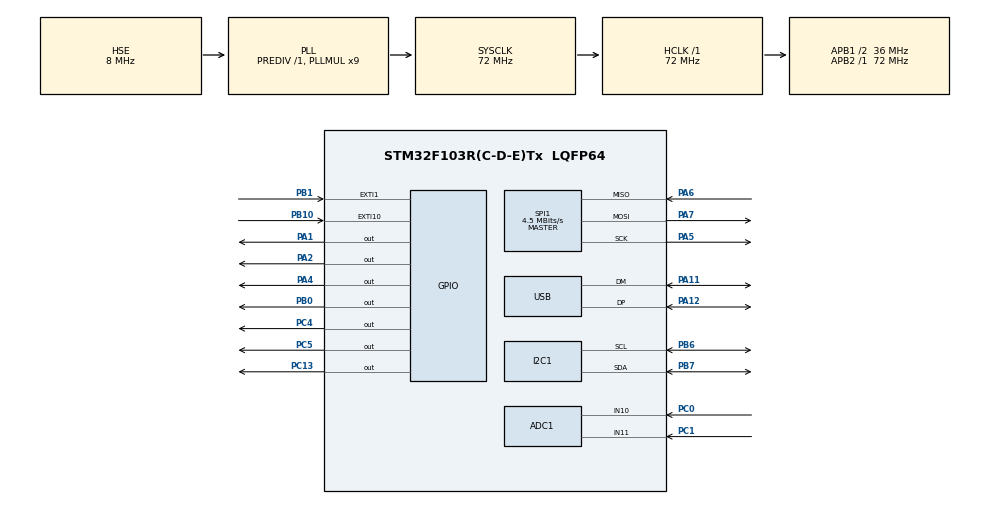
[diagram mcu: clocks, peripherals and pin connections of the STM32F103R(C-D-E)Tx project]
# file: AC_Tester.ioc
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ADC1.Channel-0\#ChannelRegularConversion=ADC_CHANNEL_11
ADC1.Channel-1\#ChannelRegularConversion=ADC_CHANNEL_10
ADC1.ContinuousConvMode=DISABLE
ADC1.ExternalTrigConv=ADC_EXTERNALTRIGCONV_T3_TRGO
ADC1.NbrOfConversion=2
ADC1.NbrOfConversionFlag=1
ADC1.Rank-0\#ChannelRegularConversion=1
ADC1.Rank-1\#ChannelRegularConversion=2
ADC1.SamplingTime-0\#ChannelRegularConversion=ADC_SAMPLETIME_1CYCLE_5
ADC1.SamplingTime-1\#ChannelRegularConversion=ADC_SAMPLETIME_1CYCLE_5
ADC1.master=1
Dma.ADC1.0.Direction=DMA_PERIPH_TO_MEMORY
Dma.ADC1.0.Instance=DMA1_Channel1
Dma.ADC1.0.MemDataAlignment=DMA_MDATAALIGN_HALFWORD
Dma.ADC1.0.MemInc=DMA_MINC_ENABLE
Dma.ADC1.0.Mode=DMA_CIRCULAR
Dma.ADC1.0.PeriphDataAlignment=DMA_PDATAALIGN_HALFWORD
Dma.ADC1.0.PeriphInc=DMA_PINC_DISABLE
Dma.ADC1.0.Priority=DMA_PRIORITY_LOW
Dma.Request0=ADC1
I2C1.I2C_Mode=I2C_Fast
Mcu.Family=STM32F1
Mcu.Name=STM32F103R(C-D-E)Tx
Mcu.Package=LQFP64
NVIC.DMA1_Channel1_IRQn=true\:0\:0\:false\:false\:true\:false\:true\:true
NVIC.EXTI1_IRQn=true\:1\:0\:true\:false\:true\:true\:true\:true
NVIC.PriorityGroup=NVIC_PRIORITYGROUP_4
NVIC.TIM2_IRQn=true\:0\:0\:false\:false\:true\:true\:true\:true
NVIC.USB_LP_CAN1_RX0_IRQn=true\:0\:0\:false\:false\:true\:false\:true\:true
PA1.Signal=GPIO_Output
PA11.Mode=Device
PA11.Signal=USB_DM
PA12.Mode=Device
PA12.Signal=USB_DP
PA13.Mode=Trace_Asynchronous_SW
PA13.Signal=SYS_JTMS-SWDIO
PA14.Mode=Trace_Asynchronous_SW
PA14.Signal=SYS_JTCK-SWCLK
PA2.Signal=GPIO_Output
PA4.Signal=GPIO_Output
PA5.Mode=Full_Duplex_Master
PA5.Signal=SPI1_SCK
PA6.Mode=Full_Duplex_Master
PA6.Signal=SPI1_MISO
PA7.Mode=Full_Duplex_Master
PA7.Signal=SPI1_MOSI
PB0.Signal=GPIO_Output
PB1.GPIO_ModeDefaultEXTI=GPIO_MODE_IT_RISING_FALLING
PB1.Signal=GPXTI1
PB10.GPIO_ModeDefaultEXTI=GPIO_MODE_IT_FALLING
PB10.Signal=GPXTI10
PB3.Mode=Trace_Asynchronous_SW
PB3.Signal=SYS_JTDO-TRACESWO
PB6.Mode=I2C
PB6.Signal=I2C1_SCL
PB7.Mode=I2C
PB7.Signal=I2C1_SDA
PC0.Signal=ADCx_IN10
PC1.Signal=ADCx_IN11
PC13-TAMPER-RTC.Signal=GPIO_Output
PC4.Signal=GPIO_Output
PC5.Signal=GPIO_Output
PD0-OSC_IN.Mode=HSE-External-Oscillator
PD0-OSC_IN.Signal=RCC_OSC_IN
PD1-OSC_OUT.Mode=HSE-External-Oscillator
PD1-OSC_OUT.Signal=RCC_OSC_OUT
ProjectManager.HeapSize=0x200
ProjectManager.StackSize=0x400
ProjectManager.TargetToolchain=STM32CubeIDE
RCC.ADCPresc=RCC_ADCPCLK2_DIV6
RCC.AHBFreq_Value=72000000
RCC.APB1CLKDivider=RCC_HCLK_DIV2
RCC.APB1Freq_Value=36000000
RCC.APB1TimFreq_Value=72000000
RCC.APB2Freq_Value=72000000
RCC.APB2TimFreq_Value=72000000
RCC.HCLKFreq_Value=72000000
RCC.PLLMUL=RCC_PLL_MUL9
RCC.SYSCLKFreq_VALUE=72000000
RCC.SYSCLKSource=RCC_SYSCLKSOURCE_PLLCLK
RCC.USBFreq_Value=48000000
RCC.USBPrescaler=RCC_USBCLKSOURCE_PLL_DIV1_5
SH.ADCx_IN10.0=ADC1_IN10,IN10
SH.ADCx_IN11.0=ADC1_IN11,IN11
SPI1.BaudRatePrescaler=SPI_BAUDRATEPRESCALER_16
SPI1.CLKPhase=SPI_PHASE_2EDGE
SPI1.CalculateBaudRate=4.5 MBits/s
SPI1.Direction=SPI_DIRECTION_2LINES
SPI1.Mode=SPI_MODE_MASTER
SPI1.VirtualType=VM_MASTER
TIM2.Prescaler=71
TIM3.Period=180
TIM3.Prescaler=0
TIM3.TIM_MasterOutputTrigger=TIM_TRGO_UPDATE
TIM3.TIM_MasterSlaveMode=TIM_MASTERSLAVEMODE_ENABLE
USB_DEVICE.CLASS_NAME_FS=CDC
USB_DEVICE.VirtualMode=Cdc
USB_DEVICE.VirtualModeFS=Cdc_FS
VP_TIM2_VS_ClockSourceINT.Mode=Internal
VP_TIM3_VS_ClockSourceINT.Mode=Internal
VP_USB_DEVICE_VS_USB_DEVICE_CDC_FS.Mode=CDC_FS
board=custom

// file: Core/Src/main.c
/* USER CODE BEGIN Header */
/**
  ******************************************************************************
  * @file           : main.c
  * @brief          : Main program body
  ******************************************************************************
  * @attention
  *
  * Copyright (c) 2025 STMicroelectronics.
  * All rights reserved.
  *
  * This software is licensed under terms that can be found in the LICENSE file
  * in the root directory of this software component.
  * If no LICENSE file comes with this software, it is provided AS-IS.
  *
  ******************************************************************************
  */
/* USER CODE END Header */
#include "main.h"
#include "usb_device.h"

/* USER CODE BEGIN Includes */

#include "AC_T_globals.h"

/* USER CODE END Includes */

ADC_HandleTypeDef hadc1;
DMA_HandleTypeDef hdma_adc1;

I2C_HandleTypeDef hi2c1;

SPI_HandleTypeDef hspi1;

TIM_HandleTypeDef htim2;
TIM_HandleTypeDef htim3;

void SystemClock_Config(void);
static void MX_GPIO_Init(void);
static void MX_DMA_Init(void);
static void MX_ADC1_Init(void);
static void MX_I2C1_Init(void);
static void MX_SPI1_Init(void);
static void MX_TIM2_Init(void);
static void MX_TIM3_Init(void);

int main(void)
{

  /* MCU Configuration--------------------------------------------------------*/

  /* Reset of all peripherals, Initializes the Flash interface and the Systick. */
  HAL_Init();

  /* Configure the system clock */
  SystemClock_Config();

  /* Initialize all configured peripherals */
  MX_GPIO_Init();
  MX_DMA_Init();
  MX_ADC1_Init();
  MX_I2C1_Init();
  MX_SPI1_Init();
  MX_USB_DEVICE_Init();
  MX_TIM2_Init();
  MX_TIM3_Init();
  /* USER CODE BEGIN 2 */

  hardwareInterfaceInit();
  AdcInit();

  initMyScheduler();

  /* USER CODE END 2 */

  /* Infinite loop */
  /* USER CODE BEGIN WHILE */
  while (1)
  {
	  runMyScheduler();

    /* USER CODE END WHILE */

  }
}

void SystemClock_Config(void)
{
  RCC_OscInitTypeDef RCC_OscInitStruct = {0};
  RCC_ClkInitTypeDef RCC_ClkInitStruct = {0};
  RCC_PeriphCLKInitTypeDef PeriphClkInit = {0};

  /** Initializes the RCC Oscillators according to the specified parameters
  * in the RCC_OscInitTypeDef structure.
  */
  RCC_OscInitStruct.OscillatorType = RCC_OSCILLATORTYPE_HSE;
  RCC_OscInitStruct.HSEState = RCC_HSE_ON;
  RCC_OscInitStruct.HSEPredivValue = RCC_HSE_PREDIV_DIV1;
  RCC_OscInitStruct.HSIState = RCC_HSI_ON;
  RCC_OscInitStruct.PLL.PLLState = RCC_PLL_ON;
  RCC_OscInitStruct.PLL.PLLSource = RCC_PLLSOURCE_HSE;
  RCC_OscInitStruct.PLL.PLLMUL = RCC_PLL_MUL9;
  if (HAL_RCC_OscConfig(&RCC_OscInitStruct) != HAL_OK)
  {
    Error_Handler();
  }

  /** Initializes the CPU, AHB and APB buses clocks
  */
  RCC_ClkInitStruct.ClockType = RCC_CLOCKTYPE_HCLK|RCC_CLOCKTYPE_SYSCLK
                              |RCC_CLOCKTYPE_PCLK1|RCC_CLOCKTYPE_PCLK2;
  RCC_ClkInitStruct.SYSCLKSource = RCC_SYSCLKSOURCE_PLLCLK;
  RCC_ClkInitStruct.AHBCLKDivider = RCC_SYSCLK_DIV1;
  RCC_ClkInitStruct.APB1CLKDivider = RCC_HCLK_DIV2;
  RCC_ClkInitStruct.APB2CLKDivider = RCC_HCLK_DIV1;

  if (HAL_RCC_ClockConfig(&RCC_ClkInitStruct, FLASH_LATENCY_2) != HAL_OK)
  {
    Error_Handler();
  }
  PeriphClkInit.PeriphClockSelection = RCC_PERIPHCLK_ADC|RCC_PERIPHCLK_USB;
  PeriphClkInit.AdcClockSelection = RCC_ADCPCLK2_DIV6;
  PeriphClkInit.UsbClockSelection = RCC_USBCLKSOURCE_PLL_DIV1_5;
  if (HAL_RCCEx_PeriphCLKConfig(&PeriphClkInit) != HAL_OK)
  {
    Error_Handler();
  }
}

static void MX_ADC1_Init(void)
{

  ADC_ChannelConfTypeDef sConfig = {0};

  /** Common config
  */
  hadc1.Instance = ADC1;
  hadc1.Init.ScanConvMode = ADC_SCAN_ENABLE;
  hadc1.Init.ContinuousConvMode = DISABLE;
  hadc1.Init.DiscontinuousConvMode = DISABLE;
  hadc1.Init.ExternalTrigConv = ADC_EXTERNALTRIGCONV_T3_TRGO;
  hadc1.Init.DataAlign = ADC_DATAALIGN_RIGHT;
  hadc1.Init.NbrOfConversion = 2;
  if (HAL_ADC_Init(&hadc1) != HAL_OK)
  {
    Error_Handler();
  }

  /** Configure Regular Channel
  */
  sConfig.Channel = ADC_CHANNEL_11;
  sConfig.Rank = ADC_REGULAR_RANK_1;
  sConfig.SamplingTime = ADC_SAMPLETIME_1CYCLE_5;
  if (HAL_ADC_ConfigChannel(&hadc1, &sConfig) != HAL_OK)
  {
    Error_Handler();
  }

  /** Configure Regular Channel
  */
  sConfig.Channel = ADC_CHANNEL_10;
  sConfig.Rank = ADC_REGULAR_RANK_2;
  if (HAL_ADC_ConfigChannel(&hadc1, &sConfig) != HAL_OK)
  {
    Error_Handler();
  }

}

static void MX_I2C1_Init(void)
{

  hi2c1.Instance = I2C1;
  hi2c1.Init.ClockSpeed = 400000;
  hi2c1.Init.DutyCycle = I2C_DUTYCYCLE_2;
  hi2c1.Init.OwnAddress1 = 0;
  hi2c1.Init.AddressingMode = I2C_ADDRESSINGMODE_7BIT;
  hi2c1.Init.DualAddressMode = I2C_DUALADDRESS_DISABLE;
  hi2c1.Init.OwnAddress2 = 0;
  hi2c1.Init.GeneralCallMode = I2C_GENERALCALL_DISABLE;
  hi2c1.Init.NoStretchMode = I2C_NOSTRETCH_DISABLE;
  if (HAL_I2C_Init(&hi2c1) != HAL_OK)
  {
    Error_Handler();
  }

}

static void MX_SPI1_Init(void)
{

  /* SPI1 parameter configuration*/
  hspi1.Instance = SPI1;
  hspi1.Init.Mode = SPI_MODE_MASTER;
  hspi1.Init.Direction = SPI_DIRECTION_2LINES;
  hspi1.Init.DataSize = SPI_DATASIZE_8BIT;
  hspi1.Init.CLKPolarity = SPI_POLARITY_LOW;
  hspi1.Init.CLKPhase = SPI_PHASE_2EDGE;
  hspi1.Init.NSS = SPI_NSS_SOFT;
  hspi1.Init.BaudRatePrescaler = SPI_BAUDRATEPRESCALER_16;
  hspi1.Init.FirstBit = SPI_FIRSTBIT_MSB;
  hspi1.Init.TIMode = SPI_TIMODE_DISABLE;
  hspi1.Init.CRCCalculation = SPI_CRCCALCULATION_DISABLE;
  hspi1.Init.CRCPolynomial = 10;
  if (HAL_SPI_Init(&hspi1) != HAL_OK)
  {
    Error_Handler();
  }

}

static void MX_TIM2_Init(void)
{

  TIM_ClockConfigTypeDef sClockSourceConfig = {0};
  TIM_MasterConfigTypeDef sMasterConfig = {0};

  htim2.Instance = TIM2;
  htim2.Init.Prescaler = 71;
  htim2.Init.CounterMode = TIM_COUNTERMODE_UP;
  htim2.Init.Period = 65535;
  htim2.Init.ClockDivision = TIM_CLOCKDIVISION_DIV1;
  htim2.Init.AutoReloadPreload = TIM_AUTORELOAD_PRELOAD_DISABLE;
  if (HAL_TIM_Base_Init(&htim2) != HAL_OK)
  {
    Error_Handler();
  }
  sClockSourceConfig.ClockSource = TIM_CLOCKSOURCE_INTERNAL;
  if (HAL_TIM_ConfigClockSource(&htim2, &sClockSourceConfig) != HAL_OK)
  {
    Error_Handler();
  }
  sMasterConfig.MasterOutputTrigger = TIM_TRGO_RESET;
  sMasterConfig.MasterSlaveMode = TIM_MASTERSLAVEMODE_DISABLE;
  if (HAL_TIMEx_MasterConfigSynchronization(&htim2, &sMasterConfig) != HAL_OK)
  {
    Error_Handler();
  }

}

static void MX_TIM3_Init(void)
{

  TIM_ClockConfigTypeDef sClockSourceConfig = {0};
  TIM_MasterConfigTypeDef sMasterConfig = {0};

  htim3.Instance = TIM3;
  htim3.Init.Prescaler = 0;
  htim3.Init.CounterMode = TIM_COUNTERMODE_UP;
  htim3.Init.Period = 180;
  htim3.Init.ClockDivision = TIM_CLOCKDIVISION_DIV1;
  htim3.Init.AutoReloadPreload = TIM_AUTORELOAD_PRELOAD_DISABLE;
  if (HAL_TIM_Base_Init(&htim3) != HAL_OK)
  {
    Error_Handler();
  }
  sClockSourceConfig.ClockSource = TIM_CLOCKSOURCE_INTERNAL;
  if (HAL_TIM_ConfigClockSource(&htim3, &sClockSourceConfig) != HAL_OK)
  {
    Error_Handler();
  }
  sMasterConfig.MasterOutputTrigger = TIM_TRGO_UPDATE;
  sMasterConfig.MasterSlaveMode = TIM_MASTERSLAVEMODE_ENABLE;
  if (HAL_TIMEx_MasterConfigSynchronization(&htim3, &sMasterConfig) != HAL_OK)
  {
    Error_Handler();
  }

}

static void MX_DMA_Init(void)
{

  /* DMA controller clock enable */
  __HAL_RCC_DMA1_CLK_ENABLE();

  /* DMA interrupt init */
  /* DMA1_Channel1_IRQn interrupt configuration */
  HAL_NVIC_SetPriority(DMA1_Channel1_IRQn, 0, 0);
  HAL_NVIC_EnableIRQ(DMA1_Channel1_IRQn);

}

static void MX_GPIO_Init(void)
{
  GPIO_InitTypeDef GPIO_InitStruct = {0};

  /* GPIO Ports Clock Enable */
  __HAL_RCC_GPIOC_CLK_ENABLE();
  __HAL_RCC_GPIOD_CLK_ENABLE();
  __HAL_RCC_GPIOA_CLK_ENABLE();
  __HAL_RCC_GPIOB_CLK_ENABLE();

  /*Configure GPIO pin Output Level */
  HAL_GPIO_WritePin(GPIOC, GPIO_PIN_13|GPIO_PIN_4|GPIO_PIN_5, GPIO_PIN_RESET);

  /*Configure GPIO pin Output Level */
  HAL_GPIO_WritePin(GPIOA, GPIO_PIN_1|GPIO_PIN_2|GPIO_PIN_4, GPIO_PIN_RESET);

  /*Configure GPIO pin Output Level */
  HAL_GPIO_WritePin(GPIOB, GPIO_PIN_0, GPIO_PIN_RESET);

  /*Configure GPIO pins : PC13 PC4 PC5 */
  GPIO_InitStruct.Pin = GPIO_PIN_13|GPIO_PIN_4|GPIO_PIN_5;
  GPIO_InitStruct.Mode = GPIO_MODE_OUTPUT_PP;
  GPIO_InitStruct.Pull = GPIO_NOPULL;
  GPIO_InitStruct.Speed = GPIO_SPEED_FREQ_LOW;
  HAL_GPIO_Init(GPIOC, &GPIO_InitStruct);

  /*Configure GPIO pins : PA1 PA2 PA4 */
  GPIO_InitStruct.Pin = GPIO_PIN_1|GPIO_PIN_2|GPIO_PIN_4;
  GPIO_InitStruct.Mode = GPIO_MODE_OUTPUT_PP;
  GPIO_InitStruct.Pull = GPIO_NOPULL;
  GPIO_InitStruct.Speed = GPIO_SPEED_FREQ_LOW;
  HAL_GPIO_Init(GPIOA, &GPIO_InitStruct);

  /*Configure GPIO pin : PB0 */
  GPIO_InitStruct.Pin = GPIO_PIN_0;
  GPIO_InitStruct.Mode = GPIO_MODE_OUTPUT_PP;
  GPIO_InitStruct.Pull = GPIO_NOPULL;
  GPIO_InitStruct.Speed = GPIO_SPEED_FREQ_LOW;
  HAL_GPIO_Init(GPIOB, &GPIO_InitStruct);

  /*Configure GPIO pin : PB1 */
  GPIO_InitStruct.Pin = GPIO_PIN_1;
  GPIO_InitStruct.Mode = GPIO_MODE_IT_RISING_FALLING;
  GPIO_InitStruct.Pull = GPIO_NOPULL;
  HAL_GPIO_Init(GPIOB, &GPIO_InitStruct);

  /*Configure GPIO pin : PB10 */
  GPIO_InitStruct.Pin = GPIO_PIN_10;
  GPIO_InitStruct.Mode = GPIO_MODE_IT_FALLING;
  GPIO_InitStruct.Pull = GPIO_NOPULL;
  HAL_GPIO_Init(GPIOB, &GPIO_InitStruct);

  /* EXTI interrupt init*/
  HAL_NVIC_SetPriority(EXTI1_IRQn, 1, 0);
  HAL_NVIC_EnableIRQ(EXTI1_IRQn);

}

void Error_Handler(void)
{
  __disable_irq();
  while (1)
  {
  }
}
